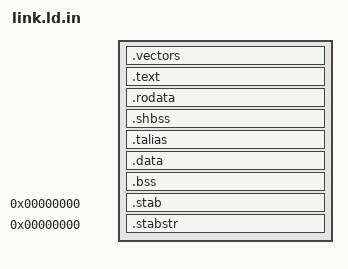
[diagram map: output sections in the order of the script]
/* Copyright (c) 2012-2013 by the author(s)
 *
 * Permission is hereby granted, free of charge, to any person obtaining a copy
 * of this software and associated documentation files (the "Software"), to deal
 * in the Software without restriction, including without limitation the rights
 * to use, copy, modify, merge, publish, distribute, sublicense, and/or sell
 * copies of the Software, and to permit persons to whom the Software is
 * furnished to do so, subject to the following conditions:
 *
 * The above copyright notice and this permission notice shall be included in
 * all copies or substantial portions of the Software.
 *
 * THE SOFTWARE IS PROVIDED "AS IS", WITHOUT WARRANTY OF ANY KIND, EXPRESS OR
 * IMPLIED, INCLUDING BUT NOT LIMITED TO THE WARRANTIES OF MERCHANTABILITY,
 * FITNESS FOR A PARTICULAR PURPOSE AND NONINFRINGEMENT. IN NO EVENT SHALL THE
 * AUTHORS OR COPYRIGHT HOLDERS BE LIABLE FOR ANY CLAIM, DAMAGES OR OTHER
 * LIABILITY, WHETHER IN AN ACTION OF CONTRACT, TORT OR OTHERWISE, ARISING FROM,
 * OUT OF OR IN CONNECTION WITH THE SOFTWARE OR THE USE OR OTHER DEALINGS IN
 * THE SOFTWARE.
 *
 * Author(s):
 *   Stefan Wallentowitz <stefan.wallentowitz@tum.de>
 */

OUTPUT_ARCH(or32)
SEARCH_DIR(.)
__DYNAMIC  =  0;

MEMORY
{
	vectors : ORIGIN = 0, LENGTH = 0x2000
	ram     : ORIGIN = 0x2000, LENGTH = (${MEMSIZE} - 0x2000)
}


/*
 * Allocate the stack to be at the top of memory, since the stack
 * grows down.
 */
PROVIDE (stack = ${MEMSIZE} - 4);
PROVIDE (_stack = ${MEMSIZE} - 4);

SECTIONS
{	
	.vectors :
	{	
		*(.vectors)
	} > vectors
	.text : {
		_stext = .;
		*(.text)
		_etext  =  .;
		__CTOR_LIST__ = .;
		LONG((__CTOR_END__ - __CTOR_LIST__) / 4 - 2)
		*(.ctors)
		LONG(0)
		__CTOR_END__ = .;
		__DTOR_LIST__ = .;
		LONG((__DTOR_END__ - __DTOR_LIST__) / 4 - 2)
		*(.dtors)
		LONG(0)
		__DTOR_END__ = .;
		*(.lit)
		*(.shdata)
		_endtext = .;
	}  > ram

	.rodata : {
		*(.rodata);
		*(.rodata.*)
	} > ram
	
	.shbss :
	{
		*(.shbss)
	} > ram
	
	.talias :
	{ 
	}  > ram
	
	.data : {
		sdata  =  .;
		_sdata  =  .;
		*(.data)
		edata  =  .;
		_edata  =  .;
	} > ram
	
	.bss SIZEOF(.data) + ADDR(.data) :
	{
		sbss = . ;
		_sbss = . ;
		__bss_start = ALIGN(0x8);
		___bss_start = ALIGN(0x8);
		*(.bss)
		*(COMMON)
		ebss = .;
		_ebss = .;
		__bss_end = ALIGN(0x8);
		___bss_end = ALIGN(0x8);
		end = ALIGN(0x8);
		_end = ALIGN(0x8);
		__end = ALIGN(0x8);	
	}

	.stab  0 (NOLOAD) : 
	{
		[ .stab ]
	}
	
	.stabstr  0 (NOLOAD) :
	{
		[ .stabstr ]
	}
}
